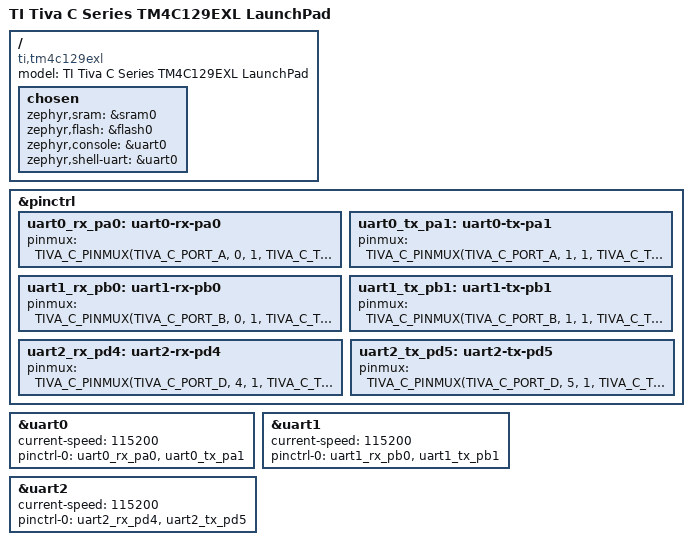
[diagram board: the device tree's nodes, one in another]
/*
 * SPDX-FileCopyrightText: Copyright (c) 2026 Linumiz
 * SPDX-FileCopyrightText: Copyright The Zephyr Project Contributors
 * SPDX-License-Identifier: Apache-2.0
 *
 * Author: Luciano Carricart <carricartluciano@gmail.com> (TM4C129 support)
 * Based on TM4C123 support by Sri Surya <srisurya@linumiz.com>
 */

/dts-v1/;

#include <ti/tm4c129encpdt.dtsi>
#include <dt-bindings/pinctrl/tiva-c-pinctrl.h>

/*
 * Pin configuration nodes for UART0, UART1 and UART2.
 * Use TIVA_C_PINMUX(port, pin, mux, type) macro.
 */
&pinctrl {
	uart0_rx_pa0: uart0-rx-pa0 {
		pinmux = <TIVA_C_PINMUX(TIVA_C_PORT_A, 0, 1, TIVA_C_TYPE_UART)>;
	};

	uart0_tx_pa1: uart0-tx-pa1 {
		pinmux = <TIVA_C_PINMUX(TIVA_C_PORT_A, 1, 1, TIVA_C_TYPE_UART)>;
	};

	uart1_rx_pb0: uart1-rx-pb0 {
		pinmux = <TIVA_C_PINMUX(TIVA_C_PORT_B, 0, 1, TIVA_C_TYPE_UART)>;
	};

	uart1_tx_pb1: uart1-tx-pb1 {
		pinmux = <TIVA_C_PINMUX(TIVA_C_PORT_B, 1, 1, TIVA_C_TYPE_UART)>;
	};

	uart2_rx_pd4: uart2-rx-pd4 {
		pinmux = <TIVA_C_PINMUX(TIVA_C_PORT_D, 4, 1, TIVA_C_TYPE_UART)>;
	};

	uart2_tx_pd5: uart2-tx-pd5 {
		pinmux = <TIVA_C_PINMUX(TIVA_C_PORT_D, 5, 1, TIVA_C_TYPE_UART)>;
	};
};

/ {
	model = "TI Tiva C Series TM4C129EXL LaunchPad";
	compatible = "ti,tm4c129exl";

	chosen {
		zephyr,sram = &sram0;
		zephyr,flash = &flash0;
		zephyr,console = &uart0;
		zephyr,shell-uart = &uart0;
	};
};

/* With JP4 and JP5 horizontal, UART0 (PA0/PA1) connects to the
 * on-board ICDI (In-Circuit Debug Interface) virtual serial port.
 */
&uart0 {
	status = "okay";
	current-speed = <115200>;
	pinctrl-0 = <&uart0_rx_pa0 &uart0_tx_pa1>;
	pinctrl-names = "default";
};

/* UART1 RX/TX on PB0/PB1, exposed at X11 pads 58/60 */
&uart1 {
	status = "okay";
	current-speed = <115200>;
	pinctrl-0 = <&uart1_rx_pb0 &uart1_tx_pb1>;
	pinctrl-names = "default";
};

/* UART2 RX/TX on PD4/PD5, exposed at X11 pads 40/38 */
&uart2 {
	status = "okay";
	current-speed = <115200>;
	pinctrl-0 = <&uart2_rx_pd4 &uart2_tx_pd5>;
	pinctrl-names = "default";
};
